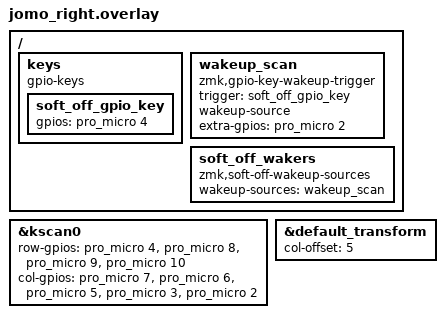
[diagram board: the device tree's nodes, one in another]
#include "jomo.dtsi" // The shared dtsi file is included in the overlay

// Label of the kscan node in the dtsi
&kscan0 {
    row-gpios
        = <&pro_micro  4 (GPIO_ACTIVE_HIGH | GPIO_PULL_DOWN)>
        , <&pro_micro  8 (GPIO_ACTIVE_HIGH | GPIO_PULL_DOWN)>
        , <&pro_micro  9 (GPIO_ACTIVE_HIGH | GPIO_PULL_DOWN)>
        , <&pro_micro 10 (GPIO_ACTIVE_HIGH | GPIO_PULL_DOWN)>
        ;

    col-gpios
        = <&pro_micro  7 GPIO_ACTIVE_HIGH>
        , <&pro_micro  6 GPIO_ACTIVE_HIGH>
        , <&pro_micro  5 GPIO_ACTIVE_HIGH>
        , <&pro_micro  3 GPIO_ACTIVE_HIGH>
        , <&pro_micro  2 GPIO_ACTIVE_HIGH>
        ;
};

&default_transform {
    col-offset = <5>;
};

/ {
    keys {
        compatible = "gpio-keys";
        soft_off_gpio_key: soft_off_gpio_key {
            gpios = <&pro_micro 4 (GPIO_ACTIVE_HIGH | GPIO_PULL_DOWN)>;
        };
    };
};

/ {
    wakeup_scan: wakeup_scan {
        compatible = "zmk,gpio-key-wakeup-trigger";
        trigger = <&soft_off_gpio_key>;
        wakeup-source;
        extra-gpios = <&pro_micro 2 GPIO_ACTIVE_HIGH>;
    };
};

/ {
    soft_off_wakers {
        compatible = "zmk,soft-off-wakeup-sources";
        wakeup-sources = <&wakeup_scan>;
    };
};
